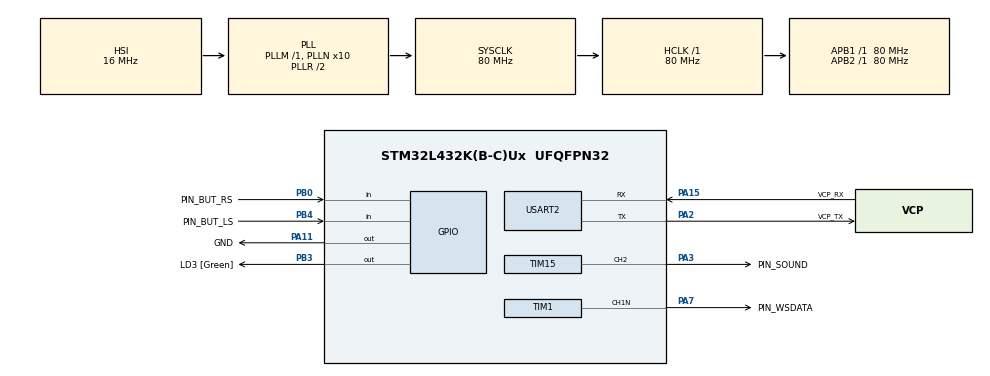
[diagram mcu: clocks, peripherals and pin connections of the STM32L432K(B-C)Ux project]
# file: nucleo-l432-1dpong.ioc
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Dma.Request0=TIM1_CH1
Dma.TIM1_CH1.0.Direction=DMA_MEMORY_TO_PERIPH
Dma.TIM1_CH1.0.Instance=DMA1_Channel2
Dma.TIM1_CH1.0.MemDataAlignment=DMA_MDATAALIGN_BYTE
Dma.TIM1_CH1.0.MemInc=DMA_MINC_ENABLE
Dma.TIM1_CH1.0.Mode=DMA_NORMAL
Dma.TIM1_CH1.0.PeriphDataAlignment=DMA_PDATAALIGN_HALFWORD
Dma.TIM1_CH1.0.PeriphInc=DMA_PINC_DISABLE
Dma.TIM1_CH1.0.Priority=DMA_PRIORITY_VERY_HIGH
Mcu.Family=STM32L4
Mcu.Name=STM32L432K(B-C)Ux
Mcu.Package=UFQFPN32
NVIC.DMA1_Channel2_IRQn=true\:0\:0\:false\:false\:true\:false\:true\:true
NVIC.PriorityGroup=NVIC_PRIORITYGROUP_4
PA0.GPIO_Label=MCO [High speed clock in]
PA0.Mode=HSE-External-Clock-Source-for-LittleOrca
PA0.Signal=RCC_CK_IN
PA11.GPIO_Label=GND
PA11.Signal=GPIO_Output
PA13\ (JTMS-SWDIO).GPIO_Label=SWDIO
PA13\ (JTMS-SWDIO).Mode=Serial_Wire
PA13\ (JTMS-SWDIO).Signal=SYS_JTMS-SWDIO
PA14\ (JTCK-SWCLK).GPIO_Label=SWCLK
PA14\ (JTCK-SWCLK).Mode=Serial_Wire
PA14\ (JTCK-SWCLK).Signal=SYS_JTCK-SWCLK
PA15\ (JTDI).GPIO_Label=VCP_RX
PA15\ (JTDI).Mode=Asynchronous
PA15\ (JTDI).Signal=USART2_RX
PA2.GPIO_Label=VCP_TX
PA2.Mode=Asynchronous
PA2.Signal=USART2_TX
PA3.GPIO_Label=PIN_SOUND
PA3.Signal=S_TIM15_CH2
PA7.GPIO_Label=PIN_WSDATA
PA7.GPIO_Speed=GPIO_SPEED_FREQ_VERY_HIGH
PA7.Mode=PWM Generation1 CH1N
PA7.Signal=TIM1_CH1N
PB0.GPIO_Label=PIN_BUT_RS
PB0.GPIO_PuPd=GPIO_PULLUP
PB0.Signal=GPIO_Input
PB3\ (JTDO-TRACESWO).GPIO_Label=LD3 [Green]
PB3\ (JTDO-TRACESWO).Signal=GPIO_Output
PB4\ (NJTRST).GPIO_Label=PIN_BUT_LS
PB4\ (NJTRST).GPIO_PuPd=GPIO_PULLUP
PB4\ (NJTRST).Signal=GPIO_Input
PC14-OSC32_IN\ (PC14).Mode=LSE-External-Oscillator
PC14-OSC32_IN\ (PC14).Signal=RCC_OSC32_IN
PC15-OSC32_OUT\ (PC15).Mode=LSE-External-Oscillator
PC15-OSC32_OUT\ (PC15).Signal=RCC_OSC32_OUT
ProjectManager.HeapSize=0x2000
ProjectManager.StackSize=0x400
ProjectManager.TargetToolchain=CMake
RCC.ADCFreq_Value=64000000
RCC.AHBFreq_Value=80000000
RCC.APB1Freq_Value=80000000
RCC.APB1TimFreq_Value=80000000
RCC.APB2Freq_Value=80000000
RCC.APB2TimFreq_Value=80000000
RCC.CortexFreq_Value=80000000
RCC.HCLKFreq_Value=80000000
RCC.HSE_VALUE=8000000
RCC.HSI16_VALUE=16000000
RCC.HSI48_VALUE=48000000
RCC.HSI_VALUE=16000000
RCC.MSI_VALUE=4000000
RCC.PLLMUL=RCC_PLLMUL_4
RCC.PLLN=10
RCC.PLLSourceVirtual=RCC_PLLSOURCE_HSI
RCC.SYSCLKFreq_VALUE=80000000
RCC.SYSCLKSource=RCC_SYSCLKSOURCE_PLLCLK
RCC.USBFreq_Value=64000000
RCC.VCOOutputFreq_Value=160000000
SH.S_TIM15_CH2.0=TIM15_CH2,Output Compare2 CH2
TIM1.Channel-PWM\ Generation1\ CH1N=TIM_CHANNEL_1
TIM1.OCMode_PWM-PWM\ Generation1\ CH1N=TIM_OCMODE_PWM2
TIM1.OCNPolarity_1=TIM_OCNPOLARITY_LOW
TIM1.Period=25-1
TIM1.Prescaler=4-1
TIM1.RepetitionCounter=0
TIM15.Channel-Output\ Compare2\ CH2=TIM_CHANNEL_2
TIM15.OCMode_2=TIM_OCMODE_TOGGLE
TIM15.Prescaler=5-1
USART2.VirtualMode-Asynchronous=VM_ASYNC
VP_TIM15_VS_ClockSourceINT.Mode=Internal
VP_TIM1_VS_ClockSourceINT.Mode=Internal
board=NUCLEO-L432KC

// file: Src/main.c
/* USER CODE BEGIN Header */
/**
  ******************************************************************************
  * @file           : main.c
  * @brief          : Main program body
  ******************************************************************************
  * @attention
  *
  * Copyright (c) 2025 STMicroelectronics.
  * All rights reserved.
  *
  * This software is licensed under terms that can be found in the LICENSE file
  * in the root directory of this software component.
  * If no LICENSE file comes with this software, it is provided AS-IS.
  *
  ******************************************************************************
  */
/* USER CODE END Header */
#include "main.h"

/* USER CODE BEGIN Includes */
#include "one_d_pong.h"
#include "stm32l4xx_hal_tim.h"
#include "stm32l4xx_hal_uart.h"
/* USER CODE END Includes */

TIM_HandleTypeDef htim1;
TIM_HandleTypeDef htim15;
DMA_HandleTypeDef hdma_tim1_ch1;

UART_HandleTypeDef huart2;

void SystemClock_Config(void);
static void MX_GPIO_Init(void);
static void MX_DMA_Init(void);
static void MX_TIM1_Init(void);
static void MX_USART2_UART_Init(void);
static void MX_TIM15_Init(void);

/* USER CODE BEGIN 0 */

int __io_putchar(int ch)
{
  while(!(USART2->ISR & USART_ISR_TXE));
  USART2->TDR = ch;
  return ch;
}

/* USER CODE END 0 */

int main(void)
{

  /* MCU Configuration--------------------------------------------------------*/

  /* Reset of all peripherals, Initializes the Flash interface and the Systick. */
  HAL_Init();

  /* Configure the system clock */
  SystemClock_Config();

  /* Initialize all configured peripherals */
  MX_GPIO_Init();
  MX_DMA_Init();
  MX_TIM1_Init();
  MX_USART2_UART_Init();
  MX_TIM15_Init();
  /* USER CODE BEGIN 2 */

  HAL_TIM_OC_Start(&htim15, TIM_CHANNEL_2);
  TIM15->CR1 &=~TIM_CR1_CEN;

  /* USER CODE END 2 */

  /* Infinite loop */
  /* USER CODE BEGIN WHILE */
  setup();
  while (1)
  {
    loop();
    /* USER CODE END WHILE */

  }
}

void SystemClock_Config(void)
{
  RCC_OscInitTypeDef RCC_OscInitStruct = {0};
  RCC_ClkInitTypeDef RCC_ClkInitStruct = {0};

  /** Configure the main internal regulator output voltage
  */
  if (HAL_PWREx_ControlVoltageScaling(PWR_REGULATOR_VOLTAGE_SCALE1) != HAL_OK)
  {
    Error_Handler();
  }

  /** Initializes the RCC Oscillators according to the specified parameters
  * in the RCC_OscInitTypeDef structure.
  */
  RCC_OscInitStruct.OscillatorType = RCC_OSCILLATORTYPE_HSI;
  RCC_OscInitStruct.HSIState = RCC_HSI_ON;
  RCC_OscInitStruct.HSICalibrationValue = RCC_HSICALIBRATION_DEFAULT;
  RCC_OscInitStruct.PLL.PLLState = RCC_PLL_ON;
  RCC_OscInitStruct.PLL.PLLSource = RCC_PLLSOURCE_HSI;
  RCC_OscInitStruct.PLL.PLLM = 1;
  RCC_OscInitStruct.PLL.PLLN = 10;
  RCC_OscInitStruct.PLL.PLLP = RCC_PLLP_DIV7;
  RCC_OscInitStruct.PLL.PLLQ = RCC_PLLQ_DIV2;
  RCC_OscInitStruct.PLL.PLLR = RCC_PLLR_DIV2;
  if (HAL_RCC_OscConfig(&RCC_OscInitStruct) != HAL_OK)
  {
    Error_Handler();
  }

  /** Initializes the CPU, AHB and APB buses clocks
  */
  RCC_ClkInitStruct.ClockType = RCC_CLOCKTYPE_HCLK|RCC_CLOCKTYPE_SYSCLK
                              |RCC_CLOCKTYPE_PCLK1|RCC_CLOCKTYPE_PCLK2;
  RCC_ClkInitStruct.SYSCLKSource = RCC_SYSCLKSOURCE_PLLCLK;
  RCC_ClkInitStruct.AHBCLKDivider = RCC_SYSCLK_DIV1;
  RCC_ClkInitStruct.APB1CLKDivider = RCC_HCLK_DIV1;
  RCC_ClkInitStruct.APB2CLKDivider = RCC_HCLK_DIV1;

  if (HAL_RCC_ClockConfig(&RCC_ClkInitStruct, FLASH_LATENCY_4) != HAL_OK)
  {
    Error_Handler();
  }
}

static void MX_TIM1_Init(void)
{

  TIM_ClockConfigTypeDef sClockSourceConfig = {0};
  TIM_MasterConfigTypeDef sMasterConfig = {0};
  TIM_OC_InitTypeDef sConfigOC = {0};
  TIM_BreakDeadTimeConfigTypeDef sBreakDeadTimeConfig = {0};

  htim1.Instance = TIM1;
  htim1.Init.Prescaler = 4-1;
  htim1.Init.CounterMode = TIM_COUNTERMODE_UP;
  htim1.Init.Period = 25-1;
  htim1.Init.ClockDivision = TIM_CLOCKDIVISION_DIV1;
  htim1.Init.RepetitionCounter = 0;
  htim1.Init.AutoReloadPreload = TIM_AUTORELOAD_PRELOAD_DISABLE;
  if (HAL_TIM_Base_Init(&htim1) != HAL_OK)
  {
    Error_Handler();
  }
  sClockSourceConfig.ClockSource = TIM_CLOCKSOURCE_INTERNAL;
  if (HAL_TIM_ConfigClockSource(&htim1, &sClockSourceConfig) != HAL_OK)
  {
    Error_Handler();
  }
  if (HAL_TIM_PWM_Init(&htim1) != HAL_OK)
  {
    Error_Handler();
  }
  sMasterConfig.MasterOutputTrigger = TIM_TRGO_RESET;
  sMasterConfig.MasterOutputTrigger2 = TIM_TRGO2_RESET;
  sMasterConfig.MasterSlaveMode = TIM_MASTERSLAVEMODE_DISABLE;
  if (HAL_TIMEx_MasterConfigSynchronization(&htim1, &sMasterConfig) != HAL_OK)
  {
    Error_Handler();
  }
  sConfigOC.OCMode = TIM_OCMODE_PWM2;
  sConfigOC.Pulse = 0;
  sConfigOC.OCPolarity = TIM_OCPOLARITY_HIGH;
  sConfigOC.OCNPolarity = TIM_OCNPOLARITY_LOW;
  sConfigOC.OCFastMode = TIM_OCFAST_DISABLE;
  sConfigOC.OCIdleState = TIM_OCIDLESTATE_RESET;
  sConfigOC.OCNIdleState = TIM_OCNIDLESTATE_RESET;
  if (HAL_TIM_PWM_ConfigChannel(&htim1, &sConfigOC, TIM_CHANNEL_1) != HAL_OK)
  {
    Error_Handler();
  }
  sBreakDeadTimeConfig.OffStateRunMode = TIM_OSSR_DISABLE;
  sBreakDeadTimeConfig.OffStateIDLEMode = TIM_OSSI_DISABLE;
  sBreakDeadTimeConfig.LockLevel = TIM_LOCKLEVEL_OFF;
  sBreakDeadTimeConfig.DeadTime = 0;
  sBreakDeadTimeConfig.BreakState = TIM_BREAK_DISABLE;
  sBreakDeadTimeConfig.BreakPolarity = TIM_BREAKPOLARITY_HIGH;
  sBreakDeadTimeConfig.BreakFilter = 0;
  sBreakDeadTimeConfig.Break2State = TIM_BREAK2_DISABLE;
  sBreakDeadTimeConfig.Break2Polarity = TIM_BREAK2POLARITY_HIGH;
  sBreakDeadTimeConfig.Break2Filter = 0;
  sBreakDeadTimeConfig.AutomaticOutput = TIM_AUTOMATICOUTPUT_DISABLE;
  if (HAL_TIMEx_ConfigBreakDeadTime(&htim1, &sBreakDeadTimeConfig) != HAL_OK)
  {
    Error_Handler();
  }
  HAL_TIM_MspPostInit(&htim1);

}

static void MX_TIM15_Init(void)
{

  TIM_ClockConfigTypeDef sClockSourceConfig = {0};
  TIM_MasterConfigTypeDef sMasterConfig = {0};
  TIM_OC_InitTypeDef sConfigOC = {0};
  TIM_BreakDeadTimeConfigTypeDef sBreakDeadTimeConfig = {0};

  htim15.Instance = TIM15;
  htim15.Init.Prescaler = 5-1;
  htim15.Init.CounterMode = TIM_COUNTERMODE_UP;
  htim15.Init.Period = 65535;
  htim15.Init.ClockDivision = TIM_CLOCKDIVISION_DIV1;
  htim15.Init.RepetitionCounter = 0;
  htim15.Init.AutoReloadPreload = TIM_AUTORELOAD_PRELOAD_DISABLE;
  if (HAL_TIM_Base_Init(&htim15) != HAL_OK)
  {
    Error_Handler();
  }
  sClockSourceConfig.ClockSource = TIM_CLOCKSOURCE_INTERNAL;
  if (HAL_TIM_ConfigClockSource(&htim15, &sClockSourceConfig) != HAL_OK)
  {
    Error_Handler();
  }
  if (HAL_TIM_OC_Init(&htim15) != HAL_OK)
  {
    Error_Handler();
  }
  sMasterConfig.MasterOutputTrigger = TIM_TRGO_RESET;
  sMasterConfig.MasterSlaveMode = TIM_MASTERSLAVEMODE_DISABLE;
  if (HAL_TIMEx_MasterConfigSynchronization(&htim15, &sMasterConfig) != HAL_OK)
  {
    Error_Handler();
  }
  sConfigOC.OCMode = TIM_OCMODE_TOGGLE;
  sConfigOC.Pulse = 0;
  sConfigOC.OCPolarity = TIM_OCPOLARITY_HIGH;
  sConfigOC.OCNPolarity = TIM_OCNPOLARITY_HIGH;
  sConfigOC.OCFastMode = TIM_OCFAST_DISABLE;
  sConfigOC.OCIdleState = TIM_OCIDLESTATE_RESET;
  sConfigOC.OCNIdleState = TIM_OCNIDLESTATE_RESET;
  if (HAL_TIM_OC_ConfigChannel(&htim15, &sConfigOC, TIM_CHANNEL_2) != HAL_OK)
  {
    Error_Handler();
  }
  sBreakDeadTimeConfig.OffStateRunMode = TIM_OSSR_DISABLE;
  sBreakDeadTimeConfig.OffStateIDLEMode = TIM_OSSI_DISABLE;
  sBreakDeadTimeConfig.LockLevel = TIM_LOCKLEVEL_OFF;
  sBreakDeadTimeConfig.DeadTime = 0;
  sBreakDeadTimeConfig.BreakState = TIM_BREAK_DISABLE;
  sBreakDeadTimeConfig.BreakPolarity = TIM_BREAKPOLARITY_HIGH;
  sBreakDeadTimeConfig.AutomaticOutput = TIM_AUTOMATICOUTPUT_DISABLE;
  if (HAL_TIMEx_ConfigBreakDeadTime(&htim15, &sBreakDeadTimeConfig) != HAL_OK)
  {
    Error_Handler();
  }
  HAL_TIM_MspPostInit(&htim15);

}

static void MX_USART2_UART_Init(void)
{

  huart2.Instance = USART2;
  huart2.Init.BaudRate = 115200;
  huart2.Init.WordLength = UART_WORDLENGTH_8B;
  huart2.Init.StopBits = UART_STOPBITS_1;
  huart2.Init.Parity = UART_PARITY_NONE;
  huart2.Init.Mode = UART_MODE_TX_RX;
  huart2.Init.HwFlowCtl = UART_HWCONTROL_NONE;
  huart2.Init.OverSampling = UART_OVERSAMPLING_16;
  huart2.Init.OneBitSampling = UART_ONE_BIT_SAMPLE_DISABLE;
  huart2.AdvancedInit.AdvFeatureInit = UART_ADVFEATURE_NO_INIT;
  if (HAL_UART_Init(&huart2) != HAL_OK)
  {
    Error_Handler();
  }

}

static void MX_DMA_Init(void)
{

  /* DMA controller clock enable */
  __HAL_RCC_DMA1_CLK_ENABLE();

  /* DMA interrupt init */
  /* DMA1_Channel2_IRQn interrupt configuration */
  HAL_NVIC_SetPriority(DMA1_Channel2_IRQn, 0, 0);
  HAL_NVIC_EnableIRQ(DMA1_Channel2_IRQn);

}

static void MX_GPIO_Init(void)
{
  GPIO_InitTypeDef GPIO_InitStruct = {0};

  /* GPIO Ports Clock Enable */
  __HAL_RCC_GPIOC_CLK_ENABLE();
  __HAL_RCC_GPIOA_CLK_ENABLE();
  __HAL_RCC_GPIOB_CLK_ENABLE();

  /*Configure GPIO pin Output Level */
  HAL_GPIO_WritePin(GND_GPIO_Port, GND_Pin, GPIO_PIN_RESET);

  /*Configure GPIO pin Output Level */
  HAL_GPIO_WritePin(LD3_GPIO_Port, LD3_Pin, GPIO_PIN_RESET);

  /*Configure GPIO pins : PIN_BUT_RS_Pin PIN_BUT_LS_Pin */
  GPIO_InitStruct.Pin = PIN_BUT_RS_Pin|PIN_BUT_LS_Pin;
  GPIO_InitStruct.Mode = GPIO_MODE_INPUT;
  GPIO_InitStruct.Pull = GPIO_PULLUP;
  HAL_GPIO_Init(GPIOB, &GPIO_InitStruct);

  /*Configure GPIO pin : GND_Pin */
  GPIO_InitStruct.Pin = GND_Pin;
  GPIO_InitStruct.Mode = GPIO_MODE_OUTPUT_PP;
  GPIO_InitStruct.Pull = GPIO_NOPULL;
  GPIO_InitStruct.Speed = GPIO_SPEED_FREQ_LOW;
  HAL_GPIO_Init(GND_GPIO_Port, &GPIO_InitStruct);

  /*Configure GPIO pin : LD3_Pin */
  GPIO_InitStruct.Pin = LD3_Pin;
  GPIO_InitStruct.Mode = GPIO_MODE_OUTPUT_PP;
  GPIO_InitStruct.Pull = GPIO_NOPULL;
  GPIO_InitStruct.Speed = GPIO_SPEED_FREQ_LOW;
  HAL_GPIO_Init(LD3_GPIO_Port, &GPIO_InitStruct);

}

void Error_Handler(void)
{
  __disable_irq();
  while (1)
  {
  }
}
